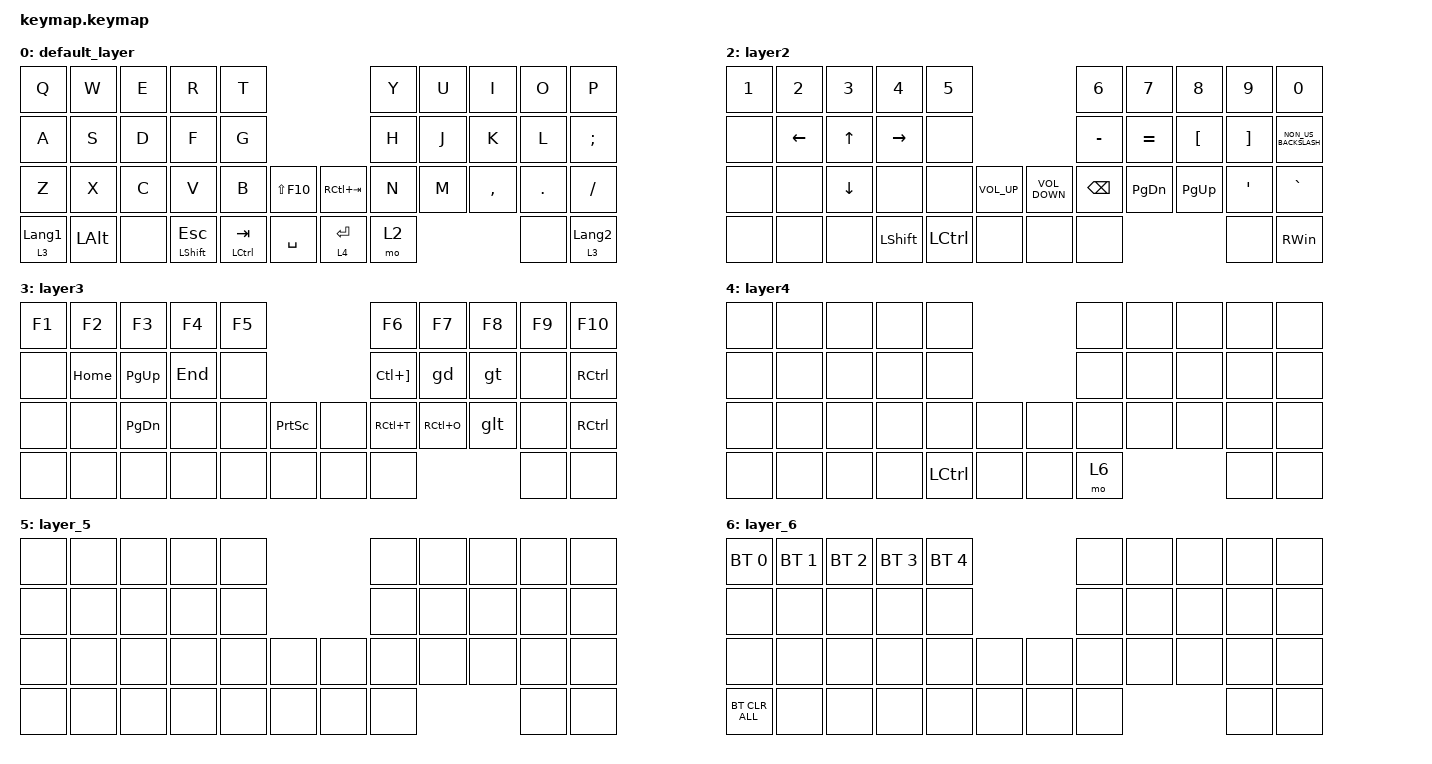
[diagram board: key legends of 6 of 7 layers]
#include <behaviors.dtsi>
#include <dt-bindings/zmk/bt.h>
#include <dt-bindings/zmk/keys.h>
#include <dt-bindings/zmk/pointing.h>

/ {
    combos { compatible = "zmk,combos"; };

    macros {
        gd: new_macro {
            compatible = "zmk,behavior-macro";
            #binding-cells = <0>;
            bindings = <&kp G &kp D>;
            label = "NEW_MACRO";
        };

        gt: gt {
            compatible = "zmk,behavior-macro";
            #binding-cells = <0>;
            bindings = <&kp G &kp T>;
            label = "GT";
        };

        glt: gtl {
            compatible = "zmk,behavior-macro";
            #binding-cells = <0>;
            bindings = <&kp G &kp LS(T)>;
            label = "GTL";
        };
    };

    keymap {
        compatible = "zmk,keymap";

        default_layer {
            bindings = <
&kp Q             &kp W         &kp E  &kp R                  &kp T                                        &kp Y  &kp U  &kp I      &kp O    &kp P
&kp A             &kp S         &kp D  &kp F                  &kp G                                        &kp H  &kp J  &kp K      &kp L    &kp SEMI
&kp Z             &kp X         &kp C  &kp V                  &kp B          &kp LS(F10)      &kp RC(TAB)  &kp N  &kp M  &kp COMMA  &kp DOT  &kp SLASH
&lt 3 LANGUAGE_1  &kp LEFT_ALT  &none  &mt LEFT_SHIFT ESCAPE  &mt LCTRL TAB  &kp SPACE        &lt 4 ENTER  &mo 2                    &none    &lt 3 LANGUAGE_2
            >;
        };

        aml {
            bindings = <
&none  &none  &none  &none  &none                    &none     &none     &none     &none     &none
&none  &none  &none  &none  &none                    &mkp MB4  &mkp MB1  &mkp MB3  &mkp MB2  &mkp MB5
&none  &none  &none  &none  &none  &none      &none  &none     &none     &none     &none     &none
&none  &none  &none  &none  &none  &none      &none  &none                         &none
            >;
        };

        layer2 {
            bindings = <
&kp NUMBER_1  &kp NUMBER_2    &kp NUMBER_3    &kp NUMBER_4    &kp N5                                             &kp NUMBER_6   &kp N7         &kp N8            &kp N9             &kp N0
&none         &kp LEFT_ARROW  &kp UP_ARROW    &kp RIGHT       &none                                              &kp MINUS      &kp EQUAL      &kp LEFT_BRACKET  &kp RIGHT_BRACKET  &kp NON_US_BACKSLASH
&none         &none           &kp DOWN_ARROW  &none           &none      &kp C_VOLUME_UP      &kp C_VOLUME_DOWN  &kp BACKSPACE  &kp PAGE_DOWN  &kp PAGE_UP       &kp APOS           &kp GRAVE
&none         &none           &none           &kp LEFT_SHIFT  &kp LCTRL  &none                &none              &none                                           &none              &kp RIGHT_WIN
            >;
        };

        layer3 {
            bindings = <
&kp F1  &kp F2    &kp F3         &kp F4   &kp F5                              &kp F6                 &kp F7     &kp F8  &kp F9  &kp F10
&none   &kp HOME  &kp PAGE_UP    &kp END  &none                               &kp LC(RIGHT_BRACKET)  &gd        &gt     &none   &kp RCTRL
&none   &none     &kp PAGE_DOWN  &none    &none   &kp PRINTSCREEN      &none  &kp RC(T)              &kp RC(O)  &glt    &none   &kp RCTRL
&none   &none     &none          &none    &none   &none                &none  &none                                     &none   &none
            >;
        };

        layer4 {
            bindings = <
&none  &none  &none  &none  &none                        &none  &none  &none  &none  &none
&none  &none  &none  &none  &none                        &none  &none  &none  &none  &none
&none  &none  &none  &none  &none      &none      &none  &none  &none  &none  &none  &none
&none  &none  &none  &none  &kp LCTRL  &none      &none  &mo 6                &none  &none
            >;
        };

        layer_5 {
            bindings = <
&none  &none  &none  &none  &none                    &none  &none  &none  &none  &none
&none  &none  &none  &none  &none                    &none  &none  &none  &none  &none
&none  &none  &none  &none  &none  &none      &none  &none  &none  &none  &none  &none
&none  &none  &none  &none  &none  &none      &none  &none                &none  &none
            >;
        };

        layer_6 {
            bindings = <
&bt BT_SEL 0    &bt BT_SEL 1  &bt BT_SEL 2  &bt BT_SEL 3  &bt BT_SEL 4                    &none  &none  &none  &none  &none
&none           &none         &none         &none         &none                           &none  &none  &none  &none  &none
&none           &none         &none         &none         &none         &none      &none  &none  &none  &none  &none  &none
&bt BT_CLR_ALL  &none         &none         &none         &none         &none      &none  &none                &none  &none
            >;
        };
    };
};
